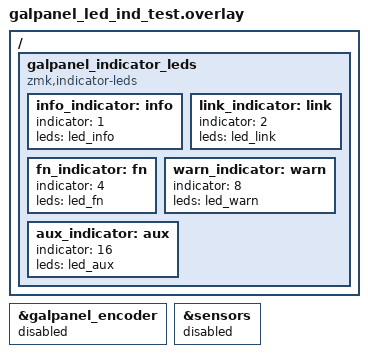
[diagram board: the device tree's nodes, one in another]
/*
 * GALPANEL V2.1 independent LED control test.
 *
 * Each GALPANEL LED is mapped to one HID indicator. Toggle Num Lock,
 * Caps Lock, and Scroll Lock from the host to verify three channels.
 * Compose and Kana remain available for a HID-output test tool.
 *
 * Copyright (c) 2026 GALPANEL contributors
 * SPDX-License-Identifier: MIT
 */

#include "galpanel.overlay"

&galpanel_encoder {
    status = "disabled";
};

&sensors {
    status = "disabled";
};

/ {
    galpanel_indicator_leds: galpanel_indicator_leds {
        compatible = "zmk,indicator-leds";

        info_indicator: info {
            indicator = <1>;
            leds = <&led_info>;
        };

        link_indicator: link {
            indicator = <2>;
            leds = <&led_link>;
        };

        fn_indicator: fn {
            indicator = <4>;
            leds = <&led_fn>;
        };

        warn_indicator: warn {
            indicator = <8>;
            leds = <&led_warn>;
        };

        aux_indicator: aux {
            indicator = <16>;
            leds = <&led_aux>;
        };
    };
};
